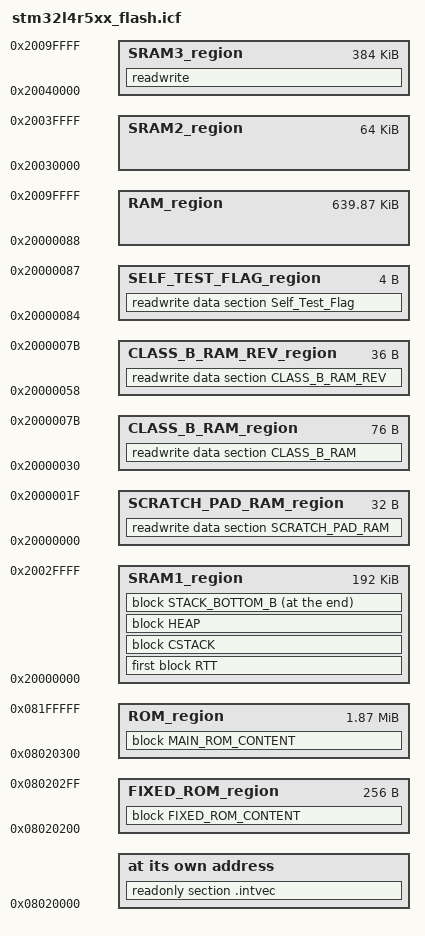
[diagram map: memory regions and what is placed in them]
/*###ICF### Section handled by ICF editor, don't touch! ****/
/*-Editor annotation file-*/
/* IcfEditorFile="$TOOLKIT_DIR$\config\ide\IcfEditor\cortex_v1_0.xml" */
/*-Specials-*/
define symbol __ICFEDIT_intvec_start__ = 0x08020000;
/*-Memory Regions-*/
define symbol __ICFEDIT_region_ROM_start__ = 0x08020300;
define symbol __ICFEDIT_region_ROM_end__   = 0x081FFFFF;
define symbol __ICFEDIT_region_RAM_start__ = 0x20000000;
define symbol __ICFEDIT_region_RAM_end__   = 0x2009FFFF;
define symbol SCRATCH_PAD_MEM_SADDR		   = __ICFEDIT_region_RAM_start__;
define symbol __ICFEDIT_region_RAM2_start__  = 0x20030000;
define symbol __ICFEDIT_region_RAM2_end__    = 0x2003FFFF;
define symbol __ICFEDIT_region_RAM3_start__  = 0x20040000;
define symbol __ICFEDIT_region_RAM3_end__    = 0x2009FFFF;

/********** TUSHAR - Placement of RAM for Self Test*************/
/* leave gaps at begin and and of class B region due to run time test overlap */
define symbol __ICFEDIT_region_SCRATCH_PAD_MEM_start__ 		= 0x20000000;
define symbol __ICFEDIT_region_SCRATCH_PAD_MEM_end__ 		= 0x2000001F;
//TODO: Add global ram variable to save status of all tests performed
define symbol __ICFEDIT_region_CLASSB_start__ 				= 0x20000030;
define symbol __ICFEDIT_region_CLASSB_midd__  				= 0x20000058;
define symbol __ICFEDIT_region_CLASSB_end__   				= 0x2000007B;
define symbol __ICFEDIT_region_SelfTestFlag_start__ 		= 0x20000084;
define symbol __ICFEDIT_region_SelfTestFlag_end__			= 0x20000087;
define symbol __ICFEDIT_region_user_RAM_start__ 			= 0x20000088;


/*-Sizes-*/
define symbol __ICFEDIT_size_cstack__ = 0x11000;
define symbol __ICFEDIT_size_heap__   = 0x10000;
/********** TUSHAR - Placement of RAM for Self Test*************/
define symbol __ICFEDIT_size_stack_bottom__ = 0x10;
/**** End of ICF editor section. ###ICF###*/

export symbol __ICFEDIT_region_user_RAM_start__;
export symbol __ICFEDIT_region_RAM_end__;
export symbol SCRATCH_PAD_MEM_SADDR;
export symbol __ICFEDIT_region_RAM3_start__;
export symbol __ICFEDIT_region_RAM3_end__;
export symbol __ICFEDIT_region_RAM2_start__;
export symbol __ICFEDIT_region_RAM2_end__;
export symbol __ICFEDIT_region_CLASSB_start__;
export symbol __ICFEDIT_region_CLASSB_end__;

/****************** ELVIS Product Header Alloc ****************/
define symbol __FIXED_region_ROM_start__   = 0x08020200;
define symbol __FIXED_region_ROM_end__     = 0x080202FF;
/**************************************************************/
define symbol __region_SRAM1_start__  = 0x20000000;
define symbol __region_SRAM1_end__    = 0x2002FFFF;
define symbol __region_SRAM2_start__  = 0x20030000;
define symbol __region_SRAM2_end__    = 0x2003FFFF;
define symbol __region_SRAM3_start__  = 0x20040000;
define symbol __region_SRAM3_end__    = 0x2009FFFF;

define memory mem with size = 4G;
define region ROM_region      = mem:[from __ICFEDIT_region_ROM_start__   to __ICFEDIT_region_ROM_end__];
define region RAM_region      = mem:[from __ICFEDIT_region_user_RAM_start__   to __ICFEDIT_region_RAM_end__];
define region SRAM1_region    = mem:[from __region_SRAM1_start__   to __region_SRAM1_end__];
define region SRAM2_region    = mem:[from __region_SRAM2_start__   to __region_SRAM2_end__];
define region SRAM3_region    = mem:[from __region_SRAM3_start__   to __region_SRAM3_end__];

/********** TUSHAR - regions definition t*************/
define region SCRATCH_PAD_RAM_region = mem:[from __ICFEDIT_region_SCRATCH_PAD_MEM_start__ to __ICFEDIT_region_SCRATCH_PAD_MEM_end__];
define region CLASS_B_RAM_region = mem:[from __ICFEDIT_region_CLASSB_start__ to __ICFEDIT_region_CLASSB_end__];
define region CLASS_B_RAM_REV_region = mem:[from __ICFEDIT_region_CLASSB_midd__ to __ICFEDIT_region_CLASSB_end__];
define region SELF_TEST_FLAG_region = mem:[from __ICFEDIT_region_SelfTestFlag_start__ to __ICFEDIT_region_SelfTestFlag_end__];

/****************** ELVIS Product Header Alloc ***********************/
define region FIXED_ROM_region= mem:[from __FIXED_region_ROM_start__   to __FIXED_region_ROM_end__];
/*********************************************************************/
define block CSTACK    with alignment = 8, size = __ICFEDIT_size_cstack__   { };
define block HEAP      with alignment = 8, size = __ICFEDIT_size_heap__     { };
define block STACK_BOTTOM_B  with alignment = 8, size = __ICFEDIT_size_stack_bottom__  { section STACK_BOTTOM };
/* SEGGER RTT (Real Time Transfer) for SystemView support */
/* See https://devzone.nordicsemi.com/f/nordic-q-a/10381/how-to-configure-rtt-with-a-fixed-address-in-iar */
define symbol Size_RTT = 0x1000;
define block RTT       with alignment = 8, size = Size_RTT                  { section RTT_section };

initialize by copy { readwrite };
do not initialize  { section .noinit, section STACK_BOTTOM, section CLASS_B_RAM, section CLASS_B_RAM_REV,
				     section SCRATCH_PAD_RAM, section Self_Test_Flag};

place at address mem:__ICFEDIT_intvec_start__ { readonly section .intvec };

/***** ELVIS - Product Header Infomation Constants *********/

define block FIXED_ROM_CONTENT with fixed order
{
	readonly section applicationDk,
	readonly section applicationVersion,
    readonly section code_crc,
	readonly section instrumentType,
	readonly section ROM_length_used
};

keep { section applicationDk };
keep { section applicationVersion };
keep { section code_crc };
keep { section instrumentType };
keep { section ROM_length_used };

/***** ELVIS - Checksum Markers *********/

define block MAIN_ROM_CONTENT with fixed order
{
	readonly section crc_start_mark,
	readonly,
	readonly section crc_end_mark
};

keep { section crc_start_mark };
keep { section crc_end_mark };


/********** TUSHAR - Placement of RAM for Self Test*************/
place in CLASS_B_RAM_region
                      { readwrite data section CLASS_B_RAM  };
                      
place in CLASS_B_RAM_REV_region
                      { readwrite data section CLASS_B_RAM_REV  };

place in SCRATCH_PAD_RAM_region
                      { readwrite data section SCRATCH_PAD_RAM };

place in SELF_TEST_FLAG_region
                      { readwrite data section Self_Test_Flag  };


/********** ELVIS - Placement in ROM and RAM *************/

/*place in ROM_region { block ROM_CONTENT };*/
place in ROM_region { block MAIN_ROM_CONTENT };
place in FIXED_ROM_region { block FIXED_ROM_CONTENT };
place in SRAM1_region { first block RTT, block CSTACK, block HEAP };
place at end of SRAM1_region {block STACK_BOTTOM_B};
place in SRAM1_region  { };
/* SRAM2 RESERVED for bootloader app API */
place in SRAM3_region { readwrite };
place in SRAM3_region { };
                        
/* See ELVIS for any explanation/information */                        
